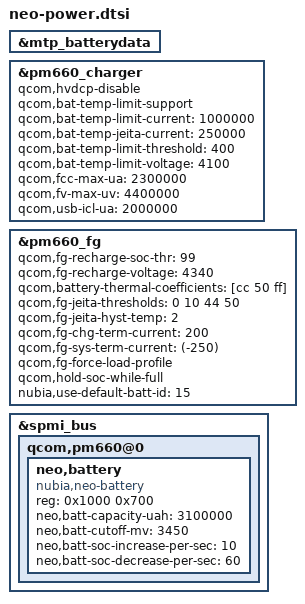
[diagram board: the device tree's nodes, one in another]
/*
 * Copyright (c) 2015-2016, The Linux Foundation. All rights reserved.
 *
 * This program is free software; you can redistribute it and/or modify
 * it under the terms of the GNU General Public License version 2 and
 * only version 2 as published by the Free Software Foundation.
 *
 * This program is distributed in the hope that it will be useful,
 * but WITHOUT ANY WARRANTY; without even the implied warranty of
 * MERCHANTABILITY or FITNESS FOR A PARTICULAR PURPOSE.  See the
 * GNU General Public License for more details.
 */

&mtp_batterydata {
	#include "fg-gen3-batterydata-atl-3450mah.dtsi"
};

&pm660_charger {
			//NUBIA ADDED BEGIN
			qcom,hvdcp-disable;
			qcom,bat-temp-limit-support;
			qcom,bat-temp-limit-current = <1000000>;
			qcom,bat-temp-jeita-current = <250000>;
			qcom,bat-temp-limit-threshold = <400>;
			qcom,bat-temp-limit-voltage = <4100>;

			qcom,fcc-max-ua = <2300000>;
			qcom,fv-max-uv = <4400000>;
			qcom,usb-icl-ua = <2000000>;
			//NUBIA ADDED ENG
};

&pm660_fg {
			//NUBIA ADDED BEGIN
			qcom,fg-recharge-soc-thr = <99>;
			qcom,fg-recharge-voltage = <4340>;
			qcom,battery-thermal-coefficients = [cc 50 ff];
			qcom,fg-jeita-thresholds = <0 10 44 50>;
			qcom,fg-jeita-hyst-temp = <2>;
			qcom,fg-chg-term-current = <200>;
			qcom,fg-sys-term-current = <(-250)>;
			qcom,fg-force-load-profile;
			qcom,hold-soc-while-full;
			nubia,use-default-batt-id = <15>;
			//NUBIA ADDED END
};

&spmi_bus {
	qcom,pm660@0 {
		//NUBIA ADDED BEGIN
		neo,battery {
			compatible = "nubia,neo-battery";
			#address-cells = <1>;
			#size-cells = <1>;
			reg = <0x1000 0x700>;
			neo,batt-capacity-uah = <3100000>;
			neo,batt-cutoff-mv = <3450>;
			neo,batt-soc-increase-per-sec = <10>;
			neo,batt-soc-decrease-per-sec = <60>;
		};
		//NUBIA ADDED END
	};
};
